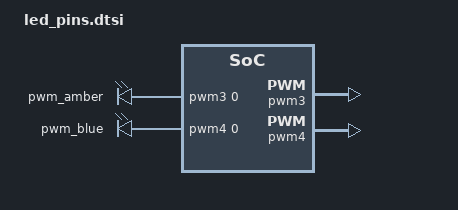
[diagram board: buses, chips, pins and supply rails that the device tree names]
/* Copyright 2022 The ChromiumOS Authors
 * Use of this source code is governed by a BSD-style license that can be
 * found in the LICENSE file.
 */

/ {
	pwmleds {
		compatible = "pwm-leds";
		pwm_amber: pwm_amber {
			pwms = <&pwm3 0 PWM_HZ(100) PWM_POLARITY_INVERTED>;
		};
		pwm_blue: pwm_blue {
			pwms = <&pwm4 0 PWM_HZ(100) PWM_POLARITY_INVERTED>;
		};
	};

	pwm-led-pins {
		compatible = "cros-ec,pwm-led-pins";

		battery_led: battery-led {
			led-id = "EC_LED_ID_BATTERY_LED";
			led-pwms = <&pwm_amber &pwm_blue>;

			color-off {
				led-color = "LED_OFF";
				led-values = <0 0>;
			};

			color-amber {
				led-color = "LED_AMBER";
				led-values = <100 0>;
			};

			color-blue {
				led-color = "LED_BLUE";
				led-values = <0 100>;
			};
		};
	};
};

/* Amber "battery charging" LED */
&pwm3 {
	status = "okay";
	clock-bus = "NPCX_CLOCK_BUS_LFCLK";
	pinctrl-0 = <&pwm3_gp80>;
	pinctrl-names = "default";
};

/* Blue "battery full" LED */
&pwm4 {
	status = "okay";
	clock-bus = "NPCX_CLOCK_BUS_LFCLK";
	pinctrl-0 = <&pwm4_gpb6>;
	pinctrl-names = "default";
};
